# LPC1125 register map
File version: 0.3
LPC1125; 2 x SSP, 1 x I2C, 3x UARTS, 12-bit ADC, 2 x 16-bit timers, 2 x 32-bit timers
CPU: CM0 r0p0, little endian, no MPU, no FPU, 2 interrupt priority bits
Registers are 32-bit, read-write, reset 0x0 unless marked. A register's access mark holds for its fields unless they carry their own. Offsets are from the block's base; lines under a group give offsets from that group; [hi:lo] are bit positions; {n}, {i} and the like mark numbered series; 'fields as' and 'values as' point back to an identical list; <NAME> marks a mode.

## Memory map
0x40000000 I2C size 0x1000 — I2C-bus interface
0x40004000 WWDT size 0x1000 — Windowed WatchDog Timer (WDT)
0x40008000 UART0 size 0x1000
0x4000C000 CT16B0 size 0x1000 — 16-bit counter/timer CT16B0/1
0x40010000 CT16B1 size 0x1000
0x40014000 CT32B0 size 0x1000 — 32-bit counter/timer CT32B0/1
0x40018000 CT32B1 size 0x1000
0x4001C000 ADC size 0x1000 — 12-bit ADC
0x40020000 UART1 size 0x1000
0x40024000 UART2 size 0x1000
0x40038000 PMU size 0x1000 — Power management unit
0x4003C000 FLASHCTRL size 0x1000 — Flash controller
0x40040000 SSP0 size 0x1000
0x40044000 IOCON size 0x1000 — I/O configuration (IOCON)
0x40048000 SYSCON size 0x1000 — System configuration (SYSCON)
0x40058000 SSP1 size 0x1000
0x50000000 GPIO0 size 0x10000
0x50010000 GPIO1 size 0x10000
0x50020000 GPIO2 size 0x10000
0x50030000 GPIO3 size 0x10000

## Interrupts
{n} PIO0_{n} (SYSCON) (n=0..11)
12 PIO1_0 (SYSCON)
13 ADC_B (ADC)
14 SSP1
15 I2C
16 CT16B0
17 CT16B1
18 CT32B0
19 CT32B1
20 SSP0
21 UART0
22 UART1
23 UART2
24 ADC_A (ADC)
25 WDT (WWDT)
26 BOD (SYSCON)
27 FLASH (FLASHCTRL)
28 GPIO3
29 GPIO2
30 GPIO1
31 GPIO0

## WWDT — Windowed WatchDog Timer (WDT)
Base 0x40004000
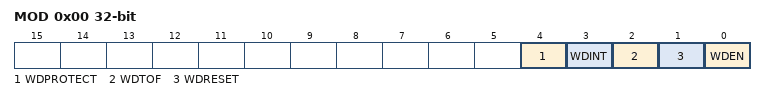
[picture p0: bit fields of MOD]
0x00 MOD — Watchdog mode register. This register contains the basic mode and status of the Watchdog Timer.
  [4] WDPROTECT — Watchdog update mode. This bit is Set Only.
    0=UPDATE (The watchdog reload value (TC) can be changed at any time.); 1=BLOCKED (The watchdog reload value (TC) can be changed only after the counter is below the value of WARNINT and WINDOW. Note: this mode is intended for use only when WDRESET =1.)
  [3] WDINT — Watchdog interrupt flag. Set when the timer reaches the value in WARNINT. Cleared by software.
  [2] WDTOF — Watchdog time-out flag. Set when the watchdog timer times out, by a feed error, or by events associated with WDPROTECT, cleared by software. Causes a chip reset if WDRESET = 1.
  [1] WDRESET — Watchdog reset enable bit. This bit is Set Only.
    0=INTERRUPT (A watchdog timeout will not cause a chip reset.); 1=RESET (A watchdog timeout will cause a chip reset.)
  [0] WDEN — Watchdog enable bit. This bit is Set Only. Setting this bit to one also locks the watchdog clock source. Once the watchdog timer is enabled, the watchdog timer clock source cannot be changed. If the watchdog timer is needed in Deep-sleep mode, the watchdog clock source must be changed to the watchdog oscillator before setting this bit to one.
    0=STOP (The watchdog timer is stopped.); 1=RUN (The watchdog timer is running.)
0x04 TC reset 0xFF — Watchdog timer constant register. This register determines the time-out value.
  [23:0] COUNT — Watchdog time-out interval.
0x08 FEED wo reset not defined — Watchdog feed sequence register. Writing 0xAA followed by 0x55 to this register reloads the Watchdog timer with the value contained in TC.
  [7:0] FEEDVAL — Feed value should be 0xAA followed by 0x55.
0x0C TV ro reset 0xFF — Watchdog timer value register. This register reads out the current value of the Watchdog timer.
  [23:0] COUNT — Counter timer value.
0x14 WARNINT — Watchdog Warning Interrupt compare value.
  [9:0] COMPVAL — Watchdog warning interrupt compare value.
0x18 WINDOW reset 0xFFFFFF — Watchdog Window compare value.
  [23:0] WINVAL — Watchdog window value.

## PMU — Power management unit
Base 0x40038000
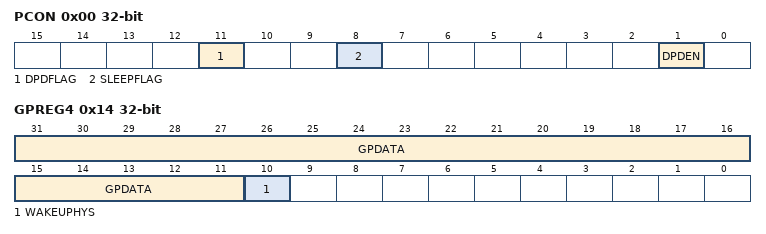
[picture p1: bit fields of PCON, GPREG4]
0x00 PCON — Power control register
  [11] DPDFLAG — Deep power-down flag
    0=NODEEPPOWERDOWN (Read: Deep power-down mode not entered. Write: No effect.); 1=DEEPPOWERDOWN (Read: Deep power-down mode entered. Write: Clear the Deep power-down flag.)
  [8] SLEEPFLAG — Sleep mode flag
    0=ACTIVE (Read: No power-down mode entered. Active mode. Write: No effect.); 1=POWERDOWN (Read: Sleep/Deep-sleep or Deep power-down mode entered. Write: Writing a 1 clears the SLEEPFLAG bit to 0.)
  [1] DPDEN — Deep power-down mode enable
    0=SLEEPDEEPSLEEP (ARM WFI will enter Sleep or Deep-sleep mode (clock to ARM Cortex-M0 core turned off).); 1=POWERDOWN (ARM WFI will enter Deep-power down mode (ARM Cortex-M0 core powered-down).)
{0x4+4i} GPREG[{i}] (i=0..3) — General purpose register 0
  [31:0] GPDATA — Data retained during Deep power-down mode.
0x14 GPREG4 — General purpose register 4
  [31:11] GPDATA — Data retained during Deep power-down mode.
  [10] WAKEUPHYS — WAKEUP pin hysteresis enable
    1=ENABLED (Hysteresis for WAKEUP pin enabled.); 0=DISABLED (Hysteresis for WAKEUP pin disabled.)
